# nrf7120E_enga_application register map
Vendor: Nordic Semiconductor; Series: nrf71; File version: 1
CPU: CM33 r0p4, little endian, MPU, FPU, 3 interrupt priority bits, 270 interrupts, 4 SAU regions
Registers are 32-bit, read-write, reset 0x0 unless marked. A register's access mark holds for its fields unless they carry their own. Offsets are from the block's base; [hi:lo] are bit positions; lines under a group give offsets from that group; {n}, {i} and the like mark numbered series; 'fields as' and 'values as' point back to an identical list.

## GLOBAL_GPIOHSPADCTRL_S — GPIO high-speed pad control
Base 0x50050400
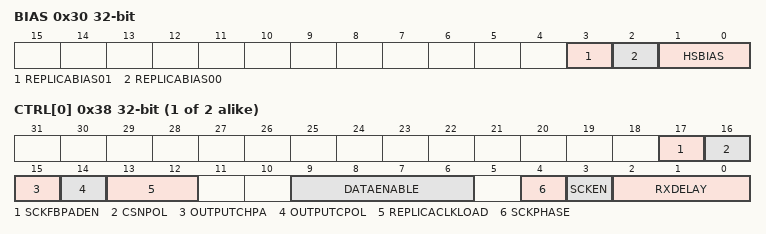
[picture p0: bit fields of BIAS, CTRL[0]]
0x30 BIAS — Bias control
  [3] REPLICABIAS01 — Slew setting for replica clock (used by the MSPI01 peripheral)
  [2] REPLICABIAS00 — Slew setting for replica clock (used by the MSPI00 peripheral)
  [1:0] HSBIAS — Slew setting for high-speed pad (higher value is faster)
{0x38+4i} CTRL[{i}] (i=0..1) — Description collection: Input sampling and buffering control (used by the MSPI0n peripheral)
  [17] SCKFBPADEN — Set IE/OE of the SCK feedback (FB) pad. This field needs to be set before SCKEN.
    0=Disabled (FB pad IE/OE disabled); 1=Enabled (FB pad IE/OE enabled)
  [16] CSNPOL — Chip Select (CSN) Polarity
    0=LOW (Active low (idle state high)); 1=HIGH (Active high (idle state low))
  [15] OUTPUTCHPA — Serial clock (SCK) phase for output data delay
    0=Leading (Sample on leading edge of clock); 1=Trailing (Sample on trailing edge of clock)
  [14] OUTPUTCPOL — Serial clock (SCK) polarity for output data delay
    0=Active high (idle state low); 1=Active low (idle state high)
  [13:12] REPLICACLKLOAD — Load capacitor used by replica clock pad
    0=Cap0p75 (Load capacitance of 0.75 pF); 1=Cap1p50 (Load capacitance of 1.5 pF); 2=Cap2p25 (Load capacitance of 2.25 pF); 3=Cap3p00 (Load capacitance of 3.0 pF)
  [9:6] DATAENABLE — Enable delayed sampling
    0=Disabled (Delayed sampling is disabled); 15=Enabled (Delayed sampling is enabled)
  [4] SCKPHASE — Feedback serial clock (SCKFB) sampling edge for input data
    0=Rising (Sample on SCK rising edge); 1=Falling (Sample on SCK falling edge)
  [3] SCKEN — Enable SCK
    0=Disabled (Delay chain is reset and delayed sampling is disabled); 1=Enabled (Delay chain and delayed sampling is active)
  [2:0] RXDELAY — Delay selection

## GLOBAL_CTRLAP_NS — Control access port 0
Base 0x40052000
Same registers: GLOBAL_CTRLAP_S 0x50052000
0x100 EVENTS_RXREADY — RXSTATUS is changed to DataPending.
  [0] EVENTS_RXREADY
    0=NotGenerated (Event not generated); 1=Generated (Event generated)
0x104 EVENTS_TXDONE — TXSTATUS is changed to NoDataPending.
  [0] EVENTS_TXDONE
    values as EVENTS_RXREADY.EVENTS_RXREADY
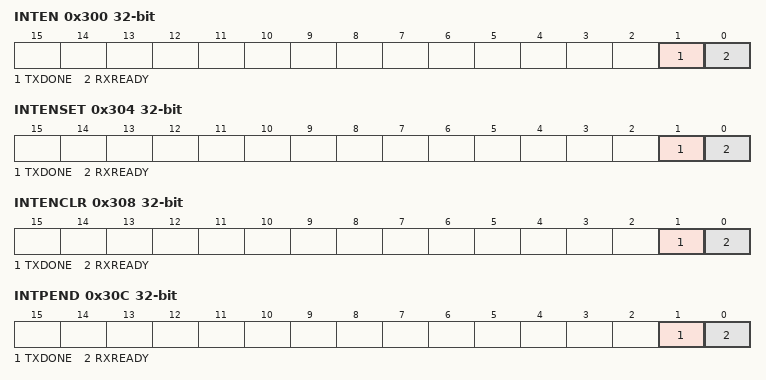
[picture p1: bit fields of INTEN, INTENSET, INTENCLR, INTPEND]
0x300 INTEN — Enable or disable interrupt
  [1] TXDONE — Enable or disable interrupt for event TXDONE
    0=Disabled; 1=Enabled
  [0] RXREADY — Enable or disable interrupt for event RXREADY
    0=Disabled; 1=Enabled
0x304 INTENSET — Enable interrupt
  [1] TXDONE write-1-sets — Write '1' to enable interrupt for event TXDONE
    on read: 0=Disabled (Read: Disabled); 1=Enabled (Read: Enabled) | on write: 1=Set (Enable)
  [0] RXREADY write-1-sets — Write '1' to enable interrupt for event RXREADY
    values as TXDONE
0x308 INTENCLR — Disable interrupt
  [1] TXDONE write-1-clears — Write '1' to disable interrupt for event TXDONE
    on read: 0=Disabled (Read: Disabled); 1=Enabled (Read: Enabled) | on write: 1=Clear (Disable)
  [0] RXREADY write-1-clears — Write '1' to disable interrupt for event RXREADY
    values as TXDONE
0x30C INTPEND ro — Pending interrupts
  [1] TXDONE — Read pending status of interrupt for event TXDONE
    on read: 0=NotPending (Read: Not pending); 1=Pending (Read: Pending)
  [0] RXREADY — Read pending status of interrupt for event RXREADY
    values as TXDONE
0x400 MAILBOX group — Unspecified
  0x00 RXDATA ro — Data sent from the debugger to the CPU.
    [31:0] RXDATA — Data received from debugger.
  0x04 RXSTATUS ro — Status to indicate if data sent from the debugger to the CPU has been read.
    [0] RXSTATUS — Status of data in register RXDATA.
      0=NoDataPending (No data is pending in register RXDATA.); 1=DataPending (Data is pending in register RXDATA.)
  0x80 TXDATA — Data sent from the CPU to the debugger.
    [31:0] TXDATA — Data sent to debugger.
  0x84 TXSTATUS ro — Status to indicate if data sent from the CPU to the debugger has been read.
    [0] TXSTATUS — Status of data in register TXDATA.
      0=NoDataPending (No data is pending in register TXDATA.); 1=DataPending (Data is pending in register TXDATA.)
0x500 ERASEPROTECT group — Unspecified
  0x00 LOCK rw-once — This register locks the ERASEPROTECT.DISABLE register from being written until next reset.
    [0] LOCK — Writing any value will lock the ERASEPROTECT.DISABLE register from being written until next reset.
      1=Locked (Register ERASEPROTECT.DISABLE is read-only.)
  0x04 DISABLE write-once — This register disables the ERASEPROTECT register and performs an ERASEALL operation.
    [31:0] KEY — The ERASEALL sequence is initiated if the value of the KEY fields are non-zero and the KEY fields match on both the CPU and debugger sides.
0x520 RESET wo — System reset request.
  [2:0] RESET — Reset request
    0=No reset is generated; 1=SoftReset (Perform a device soft reset); 2=HardReset (Perform a device hard reset); 4=PinReset (Perform a device pin reset)
